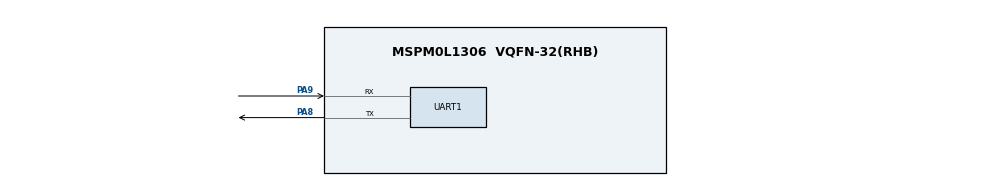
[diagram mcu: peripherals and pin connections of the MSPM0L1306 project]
// @cliArgs --board /ti/boards/LP_MSPM0L1306 --rtos nortos
//@cliArgs --device "MSPM0L130X" --package "VQFN-32(RHB)" --part "Default"
//@v2CliArgs --device "MSPM0L1306" --package "VQFN-32(RHB)"
// Port of msp430fr243x_framwrite_persistent: LED on PA0, button S2 on PA14 (pull-up, falling edge, interrupt), serial port on UART0.
const Board  = scripting.addModule("/ti/driverlib/Board", {}, false);
const GPIO   = scripting.addModule("/ti/driverlib/GPIO", {}, false);
const GPIO1  = GPIO.addInstance();
const GPIO2  = GPIO.addInstance();
const SYSCTL = scripting.addModule("/ti/driverlib/SYSCTL");
const UART   = scripting.addModule("/ti/driverlib/UART", {}, false);
const UART1  = UART.addInstance();

Board.configureUnused = true;

GPIO1.$name                          = "GPIO_LEDS";
GPIO1.associatedPins[0].$name        = "USER_LED_1";
GPIO1.associatedPins[0].assignedPort = "PORTA";
GPIO1.associatedPins[0].assignedPin  = "0";
GPIO1.associatedPins[0].initialValue = "CLEARED";

GPIO2.$name                               = "GPIO_SWITCH";
GPIO2.associatedPins[0].$name             = "S2";
GPIO2.associatedPins[0].direction         = "INPUT";
GPIO2.associatedPins[0].assignedPort      = "PORTA";
GPIO2.associatedPins[0].assignedPin       = "14";
GPIO2.associatedPins[0].internalResistor  = "PULL_UP";
GPIO2.associatedPins[0].interruptEn       = true;
GPIO2.associatedPins[0].polarity          = "FALL";

UART1.$name                    = "UART_0";
UART1.peripheral.$assign       = "UART0";
UART1.peripheral.txPin.$assign = "PA8";
UART1.peripheral.rxPin.$assign = "PA9";
UART1.targetBaudRate           = 115200;

SYSCTL.powerPolicy = "STANDBY0";
SYSCTL.clockTreeEn = true;
